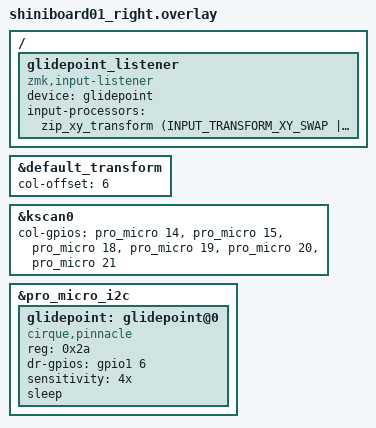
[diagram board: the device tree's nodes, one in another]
/*
 * Copyright (c) 2020 The ZMK Contributors
 *
 * SPDX-License-Identifier: MIT
 */

#include "shiniboard01.dtsi"
#include <dt-bindings/zmk/input_transform.h>

&default_transform {
    col-offset = <6>;
};

&kscan0 {
    col-gpios
        = <&pro_micro 14 GPIO_ACTIVE_HIGH>
        , <&pro_micro 15 GPIO_ACTIVE_HIGH>
        , <&pro_micro 18 GPIO_ACTIVE_HIGH>
        , <&pro_micro 19 GPIO_ACTIVE_HIGH>
        , <&pro_micro 20 GPIO_ACTIVE_HIGH>
        , <&pro_micro 21 GPIO_ACTIVE_HIGH>
        ;
};

// In this case, we added a cirque trackpad using the pro micro position i2c pins and a hand wired data ready pin
&pro_micro_i2c {
    status = "okay";
    
    glidepoint: glidepoint@0 {
        compatible = "cirque,pinnacle";
        reg = <0x2a>;
        status = "okay";
        // The aforementioned LED data pin that we're not using, hand wired to cirque DR
        dr-gpios = <&gpio1 6 (GPIO_ACTIVE_HIGH)>;

        sensitivity = "4x";
        sleep;
    };
};

/ {
    glidepoint_listener {
        compatible = "zmk,input-listener";
        device = <&glidepoint>;
        input-processors = <&zip_xy_transform (INPUT_TRANSFORM_XY_SWAP | INPUT_TRANSFORM_X_INVERT | INPUT_TRANSFORM_Y_INVERT)>;
    };
};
